# G32F002 register map
File version: 1.0
CPU: CM0PLUS r0p1, little endian, no MPU, no FPU, 4 interrupt priority bits
Registers are 32-bit, read-write, reset 0x0 unless marked. A register's access mark holds for its fields unless they carry their own. Offsets are from the block's base; [hi:lo] are bit positions.

## SPI — Serial peripheral interface
Base 0x40003000
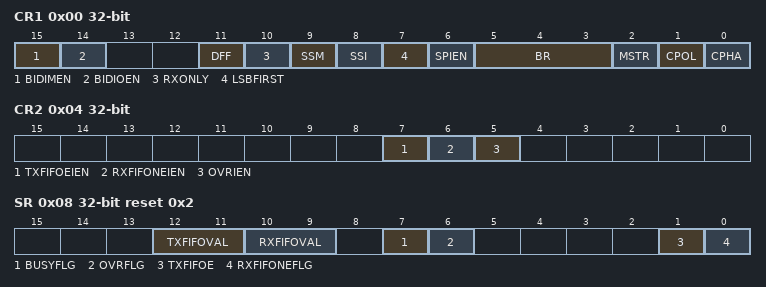
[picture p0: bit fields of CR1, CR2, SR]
0x00 CR1 — control register 1
  [15] BIDIMEN — Bidirectional data mode enable
  [14] BIDIOEN — Output enable in bidirectional mode
  [11] DFF — Data frame format
  [10] RXONLY — Receive only
  [9] SSM — Software slave management
  [8] SSI — Internal slave select
  [7] LSBFIRST — Frame format
  [6] SPIEN — SPI enable
  [5:3] BR — Baud rate control
  [2] MSTR — Master selection
  [1] CPOL — Clock polarity
  [0] CPHA — Clock phase
0x04 CR2 — control register 2
  [7] TXFIFOEIEN — Tx buffer empty interrupt enable
  [6] RXFIFONEIEN — RX buffer not empty interrupt enable
  [5] OVRIEN — Error interrupt enable
0x08 SR ro reset 0x2 — status register
  [12:11] TXFIFOVAL — Transmit FIFO Threshold
  [10:9] RXFIFOVAL — Receive FIFO Threshold
  [7] BUSYFLG — Busy flag
  [6] OVRFLG — Overrun flag
  [1] TXFIFOE — Transmit buffer empty
  [0] RXFIFONEFLG — Receive buffer not empty
0x0C DR — data register
  [15:0] DATA

## USART — Universal asynchronous receiver transmitter
Base 0x40004000
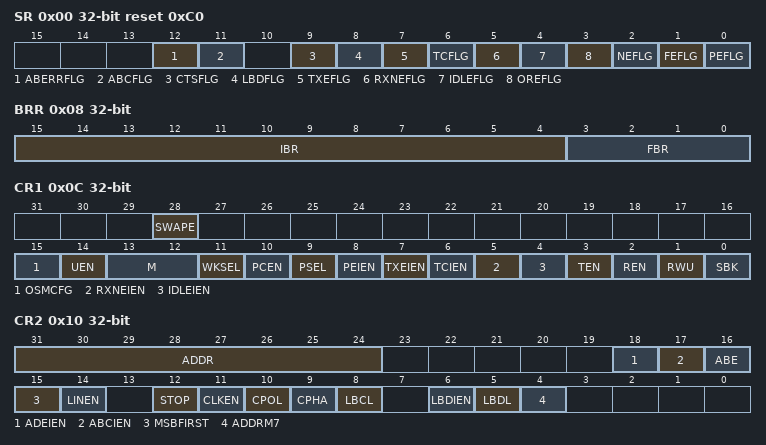
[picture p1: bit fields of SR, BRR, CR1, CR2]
0x00 SR access per field reset 0xC0
  [12] ABERRFLG rw — Auto BR error flag
  [11] ABCFLG rw — Auto BR complete flag
  [9] CTSFLG rw — CTS flag
  [8] LBDFLG rw — LIN break detection flag
  [7] TXEFLG ro — Transmit data register empty
  [6] TCFLG ro — Transmission complete
  [5] RXNEFLG ro — Read data register not empty
  [4] IDLEFLG ro — IDLE line detected
  [3] OREFLG ro — Overrun error
  [2] NEFLG ro — Noise error flag
  [1] FEFLG ro — Framing error
  [0] PEFLG ro — Parity error
0x04 DR
  [8:0] DATA — Data value
0x08 BRR
  [15:4] IBR — Integer baud rate
  [3:0] FBR — Fractional baud rate
0x0C CR1
  [28] SWAPE — Swap TX/RX Pins Function Enable
  [15] OSMCFG — Oversampling mode configure
  [14] UEN — USART enable
  [13:12] M — Word length
  [11] WKSEL — Wakeup method
  [10] PCEN — Parity control enable
  [9] PSEL — Parity selection
  [8] PEIEN — PE interrupt enable
  [7] TXEIEN — TXE interrupt enable
  [6] TCIEN — Transmission complete interrupt enable
  [5] RXNEIEN — RXNE interrupt enable
  [4] IDLEIEN — IDLE interrupt enable
  [3] TEN — Transmitter enable
  [2] REN — Receiver enable
  [1] RWU — Receiver wakeup
  [0] SBK — Send break
0x10 CR2
  [31:24] ADDR — Node address
  [18] ADEIEN — Auto baud error interrupt enable
  [17] ABCIEN — Auto baud complete interrupt enable
  [16] ABE — Auto baud enable
  [15] MSBFIRST — Most significant bit first
  [14] LINEN — LIN mode enable
  [12] STOP — STOP bits
  [11] CLKEN — Clock enable
  [10] CPOL — Clock polarity
  [9] CPHA — Clock phase
  [8] LBCL — Last bit clock pulse
  [6] LBDIEN — LIN break detection interrupt enable
  [5] LBDL — LIN break detection length
  [4] ADDRM7 — Bit select of address measure
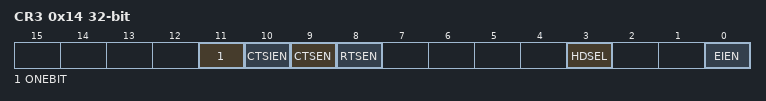
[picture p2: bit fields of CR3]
0x14 CR3
  [11] ONEBIT — Receive data sample mode
  [10] CTSIEN — CTS interrupt enable
  [9] CTSEN — CTS enable
  [8] RTSEN — RTS enable
  [3] HDSEL — Half-duplex selection
  [0] EIEN — Error interrupt enable

## I2C — Inter-Integrated Circuit
Base 0x40002000
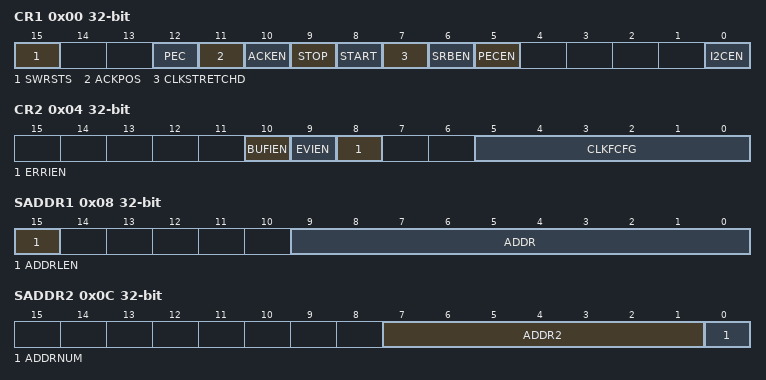
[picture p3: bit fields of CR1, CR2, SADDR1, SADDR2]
0x00 CR1 — control register 1
  [15] SWRSTS — Software Configure I2C under Reset State
  [12] PEC — Packet Error Check Transfer Enable
  [11] ACKPOS — Acknowledge /PEC Position Configure
  [10] ACKEN — Acknowledge Transfer Enable
  [9] STOP — Stop Bit Transfer
  [8] START — Start Bit Transfer
  [7] CLKSTRETCHD — Slave Mode Clock Stretching Disable
  [6] SRBEN — Slave Responds Broadcast Enable
  [5] PECEN — PEC Enable
  [0] I2CEN — I2C Enable
0x04 CR2 — control register 2
  [10] BUFIEN — Error interrupt enable
  [9] EVIEN — Event Interrupt Enable
  [8] ERRIEN — Error Interrupt Enable
  [5:0] CLKFCFG — I2C Clock Frequency Configure
0x08 SADDR1 — Slave Mode Address Register 1
  [15] ADDRLEN — Slave Address Length Configure
  [9:0] ADDR — Slave Address Setup
0x0C SADDR2 — Slave Mode Address Register 2
  [7:1] ADDR2 — Slave Dual Address Mode Address Setup
  [0] ADDRNUM — Slave Address Number Configure
0x10 DR — data register
  [7:0] DATA
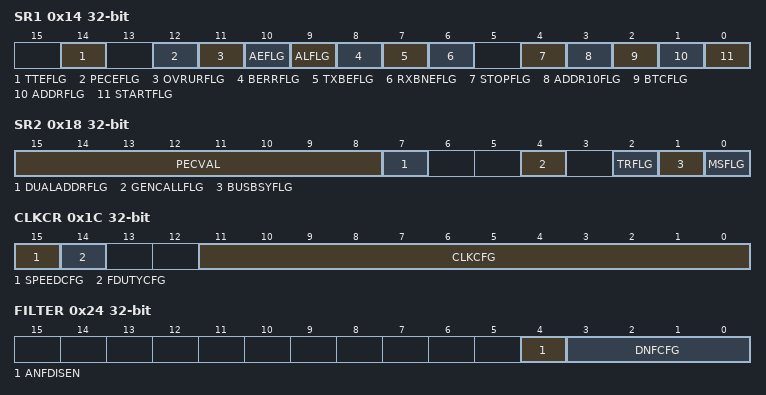
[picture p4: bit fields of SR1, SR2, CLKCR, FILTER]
0x14 SR1 access per field — Status register 1
  [14] TTEFLG rw — Timeout or Tlow Error Flag
  [12] PECEFLG rw — PEC Error in Reception Flag
  [11] OVRURFLG rw — Overrun/Underrun Flag
  [10] AEFLG rw — Acknowledge Error Flag
  [9] ALFLG rw — Master Mode Arbitration Lost Flag
  [8] BERRFLG rw — Bus Error Flag
  [7] TXBEFLG ro — Transmit Buffer Empty Flag
  [6] RXBNEFLG ro — Receive Buffer Not Empty Flag
  [4] STOPFLG ro — Stop Bit Detection Flag
  [3] ADDR10FLG ro — 10-Bit Address Header Transmit Flag
  [2] BTCFLG ro — Byte Transfer Complete Flag
  [1] ADDRFLG ro — Address Transfer Complete / Receive Match Flag
  [0] STARTFLG ro — Start Bit Sent Finished Flag
0x18 SR2 ro — Status register 2
  [15:8] PECVAL — Save Packet Error Checking Value
  [7] DUALADDRFLG — Slave Mode Received Dual Address Match Flag
  [4] GENCALLFLG — Slave Mode Received General Call Address Flag
  [2] TRFLG — Transmitter / Receiver Mode Flag
  [1] BUSBSYFLG — Bus Busy Flag
  [0] MSFLG — Master Slave Mode Flag
0x1C CLKCR — Host Clock Control Register
  [15] SPEEDCFG — Master Mode Speed Configure
  [14] FDUTYCFG — Fast Mode Duty Cycle Configure
  [11:0] CLKCFG — Clock Setup in Fast/Standard Master Mode
0x20 RISETMAX reset 0x2 — Maximum Rise Time Register
  [5:0] RISETMAX — Master Mode Maximum Rise Time in Fast/Standard Mode
0x24 FILTER — Filter Control Register
  [4] ANFDISEN — Analog Noise Filter Disable
  [3:0] DNFCFG — Digital Noise Filter Filtering Capability Configure
